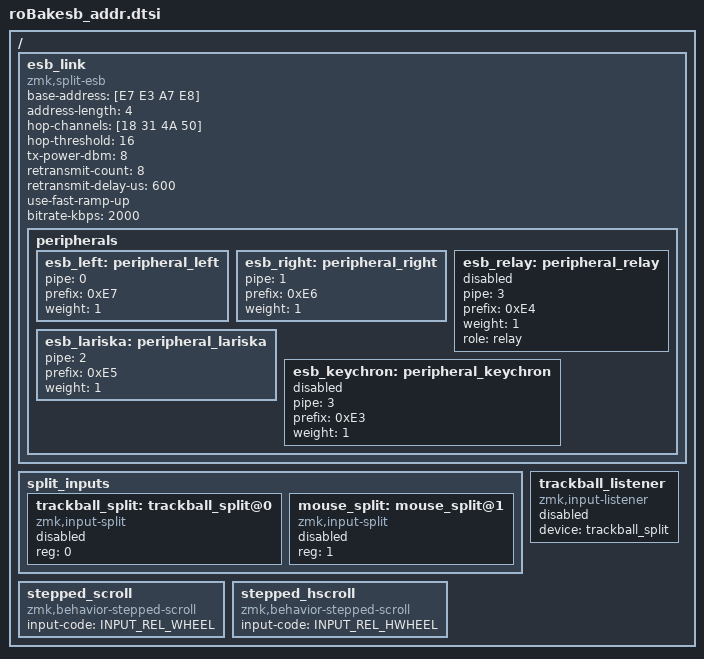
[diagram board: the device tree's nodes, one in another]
/*
 * Shared ESB link identity for the roBakesb dongle and all peripherals.
 * Every side must include the same base address, channel set, and peripheral
 * table. Each peripheral overlay selects its own entry with zmk,esb-self.
 * The trackball_listener is disabled here; the dongle overlay enables it.
 * The right peripheral overlay assigns device = <&trackball> to trackball_split.
 * The lariska peripheral assigns device = <&mou0> to mouse_split.
 */

#include <zephyr/dt-bindings/input/input-event-codes.h>

/ {
    esb_link: esb_link {
        compatible = "zmk,split-esb";
        base-address = [E7 E3 A7 E8];
        address-length = <4>;
        hop-channels = [18 31 4A 50];
        hop-threshold = <16>;

        peripherals {
            esb_left: peripheral_left {
                pipe = <0>;
                prefix = <0xE7>;
                weight = <1>;
            };

            esb_right: peripheral_right {
                pipe = <1>;
                prefix = <0xE6>;
                weight = <1>;
            };

            esb_lariska: peripheral_lariska {
                pipe = <2>;
                prefix = <0xE5>;
                weight = <1>;
            };

            /* HID relay dongle. Only used by the right-central topology
             * (roBakesb_right_central + roBakesb_relay), so it stays disabled
             * here and each of those two overlays sets it okay. A disabled
             * child is skipped by DT_FOREACH_CHILD_STATUS_OKAY, so the
             * dongle-central builds keep the same three-pipe link they had. */
            esb_relay: peripheral_relay {
                pipe = <3>;
                prefix = <0xE4>;
                weight = <1>;
                role = "relay";
                status = "disabled";
            };

            /* Keychron B1 Pro (roBakesb_keychron). A fourth ordinary key
             * peripheral on the dongle-central link, so it stays disabled
             * here and roBakesb_keychron_transform.dtsi sets it okay. Every
             * node on the link has to agree on this: the beacon is 4 bytes
             * plus 2 per *enabled* peripheral, and a node that parses a
             * different length drops it, and the hop epoch with it. So the
             * dongle, left, right, lariska and the Keychron are all built with
             * the pipe on (the roBakesb_keychron_link shield), or none are.
             *
             * Pipe 3, not 4: hop_stage_beacon refuses any pipe at or above the
             * enabled-peripheral count, so enabled pipes have to be contiguous
             * from 0. That is also the relay's pipe, so this and the relay
             * topology are mutually exclusive until one of them is moved. The
             * prefix is its own, so the addresses themselves never collide. */
            esb_keychron: peripheral_keychron {
                pipe = <3>;
                prefix = <0xE3>;
                weight = <1>;
                status = "disabled";
            };
        };

        tx-power-dbm = <8>;
        retransmit-count = <8>;
        retransmit-delay-us = <600>;
        use-fast-ramp-up;
        bitrate-kbps = <2000>;
        /* Fully lossless uplink: lossy-codes omitted deliberately. Every
         * motion batch requests an ACK, so a lost packet is retransmitted
         * instead of losing that delta outright. Mouse buttons and scroll
         * were always ACK'd; motion is the axis that has gone back and forth.
         *
         * It was briefly restored to <INPUT_EV_REL INPUT_REL_X> and
         * INPUT_REL_Y (594f142) as a probe, once split-esb v0.8.9 had taken
         * the relay link from 1-3 failures/s with 190-284-failure bursts down
         * to ~0.06/s with none. The question it was asking: whether what
         * remained was a TX FIFO backlog under fast movement, since lossy
         * motion takes a motion batch out of the retransmit budget entirely
         * (no burning retransmit-count=8 at 600us). Lossless is the better
         * default -- a dropped delta is lost cursor travel -- so it goes back
         * now that the relay link itself is healthy.
         *
         * The probe did not come back clean, though, and the number is the
         * reason this decision is still open. Measured at the host through
         * the relay, 2 ms poll, v0.8.9 on every node:
         *
         *   lossy     ~320 Hz at the pointer, ~0.06 relay TX failures/s
         *   lossless  ~190 Hz at the pointer, ~0.14 relay TX failures/s
         *
         * Both are an order of magnitude under the 1-3/s v0.8.7 baseline and
         * neither shows the bursts, so this is no longer about the stutter --
         * that was a97cb28. It is a straight trade of ~130 Hz of pointer rate
         * for motion that cannot be dropped. Lossless wins on correctness and
         * is what is set here; if the rate turns out to matter more in use,
         * the lossy hunk is one property and a four-node reflash away.
         *
         * What this costs, and it is worth knowing before reaching for lossy
         * again: with no lossy axes declared, PERIPHERAL_MOTION_TOTALS_MAX is
         * 0, so v0.8.6's running totals have nothing to heal. That feature
         * only applies to axes declared here. Lossless does not need it --
         * nothing is dropped to heal -- but it does mean high-rate trackball
         * traffic buys its reliability with airtime and peripheral battery.
         *
         * It also makes two v0.8.8/v0.8.9 commits inert again: no hop window
         * has a noack packet to exclude from its grade (5b423da) and the
         * central's pipes_acked always equals the old pipes_seen (e989fd4).
         * Nothing here sends fire-and-forget -- event_wants_ack is always
         * true, and the keepalive and relay poll both go out with noack = 0.
         *
         * Payload consequence: lariska's keepalive loses the count byte and
         * 4 bytes per lossy axis (ESB_KEEPALIVE_MOTION_BYTES), going 53 ->
         * 45. So 56 is headroom again rather than load-bearing, and 48 would
         * build -- but the rig stays at 56 so that restoring lossy-codes is a
         * one-hunk change and not a payload migration. Arithmetic in
         * roBakesb_lariska.conf.
         *
         * To go lossy again: put the lossy-codes property back (it is in
         * 594f142, and charybdis_esb_addr.dtsi still carries the exact
         * syntax), and reflash every node -- the keepalive layout changes.
         */
    };

    split_inputs {
        #address-cells = <1>;
        #size-cells = <0>;

        trackball_split: trackball_split@0 {
            compatible = "zmk,input-split";
            reg = <0>;
            status = "disabled";
        };

        mouse_split: mouse_split@1 {
            compatible = "zmk,input-split";
            reg = <1>;
            status = "disabled";
        };
    };

    trackball_listener: trackball_listener {
        compatible = "zmk,input-listener";
        status = "disabled";
        device = <&trackball_split>;
    };

    /* Defined here so all targets (dongle + every peripheral) resolve
     * &stepped_scroll from the shared roBakesb.keymap. The dongle's overlay
     * also adds stepped_scroll_il which routes the events to HID. */
    stepped_scroll: stepped_scroll {
        compatible = "zmk,behavior-stepped-scroll";
        #binding-cells = <1>;
        input-code = <INPUT_REL_WHEEL>;
    };

    /* Horizontal variant of stepped_scroll for the MB4-hold scroll layer.
     * Routed to HID by stepped_hscroll_il in the dongle overlay. */
    stepped_hscroll: stepped_hscroll {
        compatible = "zmk,behavior-stepped-scroll";
        #binding-cells = <1>;
        input-code = <INPUT_REL_HWHEEL>;
    };
};
